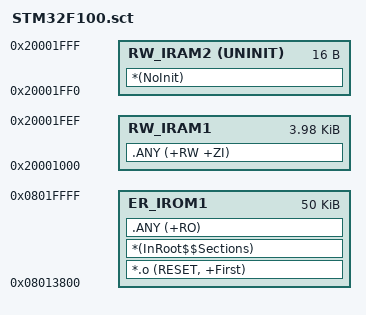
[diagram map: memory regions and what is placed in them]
; *************************************************************
; *** Scatter-Loading Description File generated by uVision ***
; *************************************************************

LR_IROM1 0x08013800 0x0000C800  {    ; load region size_region
  ER_IROM1 0x08013800 0x0000C800  {  ; load address = execution address
   *.o (RESET, +First)
   *(InRoot$$Sections)
   .ANY (+RO)
  }
  RW_IRAM1 0x20001000 0x00000FF0  {  ; RW data
   .ANY (+RW +ZI)
  }
  RW_IRAM2 0x20001FF0 UNINIT 0x00000010  {
   *(NoInit)
  }
}

